# MIK32 register map
Vendor: Mikron JSC; Series: MIK32; File version: 1.0
Registers are 32-bit, read-write, reset 0x0 unless marked. A register's access mark holds for its fields unless they carry their own. Offsets are from the block's base; [hi:lo] are bit positions; {n}, {i} and the like mark numbered series; 'fields as' and 'values as' point back to an identical list.

## TIMER32_1 — Регистры модуля TIMER32_1
Base 0x00082800
0x00 VALUE ro — Текущее значение основного таймера
  [31:0] TIM_VAL — Текущее значение счётчика
0x04 TOP reset 0xFFFFFFFF — максимальное значение счётной последовательности
  [31:0] TIM_TOP — максимальное значение счётчика (ограничивает счётную последовательность сверху)
0x08 PRESCALE — значение делителя
  [31:0] TIM_PRESCALE — Значение предварительного делителя. Предделитель вырабатывает тактовый сигнал для счёта, частота которого в целое число раз меньше входной
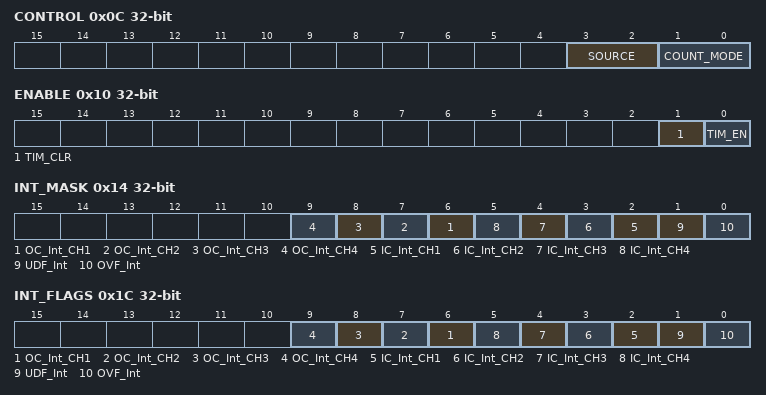
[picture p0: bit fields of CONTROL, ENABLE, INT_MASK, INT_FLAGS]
0x0C CONTROL — Конфигурационный регистр основного таймера
  [3:2] SOURCE — Выбор источника тактового сигнала для счёта
    0=APB_P_CLK (частота тактов шины APB_P); 1=TIM1 (синхронный вход тактирования TIM1); 2=TIMER32_1_Tx (вход TIMER32_1_Tx микросхемы); 3=TIM2 (асинхронный вход тактирования TIM2)
  [1:0] COUNT_MODE — Режим счёта таймера
    0=Direct (Прямой режим); 1=Reverse (Обратный режим); 2=Bidirectional (Двунаправленный режим)
0x10 ENABLE — Регистр включения таймера
  [1] TIM_CLR write-once — Сброс (обнуление) текущего значения счётчика при записи «1»
  [0] TIM_EN — Запуск/остановка работы счётчика
    0=Disable (Счётчик выключен); 1=Enable (Счётчик работает)
0x14 INT_MASK — Регистр маски прерываний
  [n+5] OC_Int_CH{n} (n=1..4) — Маска прерывания совпадения {n} канала таймера
  [n+1] IC_Int_CH{n} (n=1..4) — Маска прерывания захвата {n} канала таймера
  [1] UDF_Int — Маска прерывания опустошения счётчика
  [0] OVF_Int — Маска прерывания по переполнению счётчика
0x18 INT_CLEAR reset 0xFFFFFFFF — Регистр сброса флагов прерываний
0x1C INT_FLAGS ro — Регистр флагов прерываний
  [n+5] OC_Int_CH{n} (n=1..4) — Статус прерывания совпадения {n} канала таймера
  [n+1] IC_Int_CH{n} (n=1..4) — Статус прерывания захвата {n} канала таймера
  [1] UDF_Int — Статус прерывания опустошения счётчика
  [0] OVF_Int — Статус прерывания по переполнению счётчика
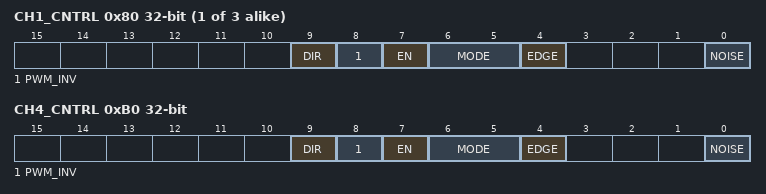
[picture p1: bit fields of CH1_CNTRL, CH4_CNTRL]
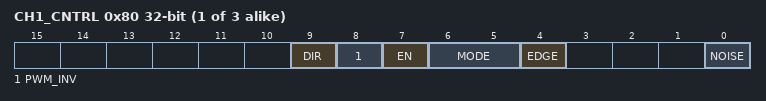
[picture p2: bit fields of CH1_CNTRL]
{0x70+0x10*i} CH{i}_CNTRL (i=1..3) — Конфигурационный регистр {i} канала
  [9] DIR ro — Направление передачи данных. Устанавливается автоматически в зависимости от режима работы (1 - выход, 0 - вход)
    1=Output (Выход); 0=Input (Вход)
  [8] PWM_INV — Тип вывода в режиме ШИМ инвертирование
    0=Direct (Прямой (не инвертированный) выход); 1=Inverted (Инвертированный выход)
  [7] EN — Включение/выключение канала
  [6:5] MODE — Режим работы канала
    1=Compare (Режим сравнения (для timer0)); 2=Capture (Режим захвата(для timer0)); 3=PWM (ШИМ)
  [4] EDGE — Режим сигнала захвата
    0=Front (фронт); 1=Back (спад)
  [0] NOISE — Управление фильтрацией входных помех на входе ic_port: 0 – фильтрация выключена; 1 – фильтрация выключена
    0=Enable (Фильтрация выключена); 1=Disable (Фильтрация включена)
{0x74+0x10*i} CH{i}_OCR (i=1..4) — Значение сравнения {i} канала
  [31:0] OCR — Значение таймера в режиме сравнения
{0x78+0x10*i} CH{i}_ICR (i=1..4) — Значение захвата {i} канала
  [31:0] ICR — Значение таймера в режиме захвата
0xB0 CH4_CNTRL — Конфигурационный регистр 4 канала
  [9] DIR ro — Направление передачи данных. Устанавливается автоматически в зависимости от режима работы (1 - выход, 0 - вход)
    1=Output (Выход); 0=Input (Вход)
  [8] PWM_INV — Тип вывода в режиме ШИМ инвертирование
    values as CH1_CNTRL.PWM_INV
  [7] EN — Включение/выключение канала
  [6:5] MODE — Режим работы канала
    values as CH1_CNTRL.MODE
  [4] EDGE — Режим сигнала захвата
    0=Front (по фронту); 1=Back (по спаду)
  [0] NOISE — Управление фильтрацией входных помех на входе ic_port: 0 – фильтрация выключена; 1 – фильтрация выключена
    values as CH1_CNTRL.NOISE

## TIMER32_2 — Регистры модуля TIMER32_2
Base 0x00082C00
Registers as TIMER32_1 (with TIMER32_1 read as TIMER32_2); these are added or differ:
{0x70+0x10*i} CH{i}_CNTRL (i=1..3) — Конфигурационный регистр {i} канала
  fields as TIMER32_1.CH4_CNTRL
